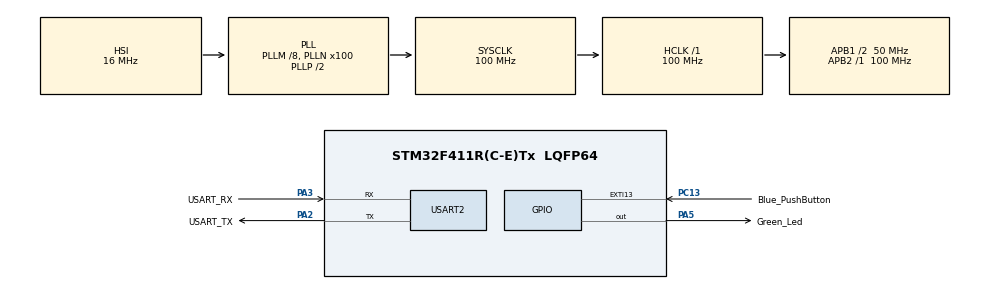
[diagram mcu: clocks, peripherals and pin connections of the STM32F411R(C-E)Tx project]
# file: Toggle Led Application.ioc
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Mcu.Family=STM32F4
Mcu.Name=STM32F411R(C-E)Tx
Mcu.Package=LQFP64
NVIC.EXTI15_10_IRQn=true\:0\:0\:false\:false\:true\:true\:true\:true
NVIC.PriorityGroup=NVIC_PRIORITYGROUP_0
NVIC.TIM1_UP_TIM10_IRQn=true\:0\:0\:false\:false\:true\:true\:true\:true
PA13.GPIO_Label=TMS
PA13.Mode=Serial_Wire
PA13.Signal=SYS_JTMS-SWDIO
PA14.GPIO_Label=TCK
PA14.Mode=Serial_Wire
PA14.Signal=SYS_JTCK-SWCLK
PA2.GPIO_Label=USART_TX
PA2.Mode=Asynchronous
PA2.Signal=USART2_TX
PA3.GPIO_Label=USART_RX
PA3.Mode=Asynchronous
PA3.Signal=USART2_RX
PA5.GPIO_Label=Green_Led
PA5.Signal=GPIO_Output
PB3.GPIO_Label=SWO
PB3.Signal=SYS_JTDO-SWO
PC13-ANTI_TAMP.GPIO_Label=Blue_PushButton
PC13-ANTI_TAMP.GPIO_ModeDefaultEXTI=GPIO_MODE_IT_FALLING
PC13-ANTI_TAMP.Signal=GPXTI13
ProjectManager.HeapSize=0x200
ProjectManager.StackSize=0x400
ProjectManager.TargetToolchain=MDK-ARM V5.32
RCC.48MHZClocksFreq_Value=50000000
RCC.AHBFreq_Value=100000000
RCC.APB1CLKDivider=RCC_HCLK_DIV2
RCC.APB1Freq_Value=50000000
RCC.APB1TimFreq_Value=100000000
RCC.APB2Freq_Value=100000000
RCC.APB2TimFreq_Value=100000000
RCC.CortexFreq_Value=100000000
RCC.FLatency-AdvancedSettings=FLASH_LATENCY_3
RCC.HCLKFreq_Value=100000000
RCC.HSE_VALUE=8000000
RCC.HSI_VALUE=16000000
RCC.LSE_VALUE=32768
RCC.PLLM=8
RCC.PLLN=100
RCC.SYSCLKFreq_VALUE=100000000
RCC.SYSCLKSource=RCC_SYSCLKSOURCE_PLLCLK
RCC.VCOOutputFreq_Value=200000000
TIM10.AutoReloadPreload=TIM_AUTORELOAD_PRELOAD_ENABLE
TIM10.Period=999
TIM10.Prescaler=99
USART2.VirtualMode=VM_ASYNC
VP_TIM10_VS_ClockSourceINT.Mode=Enable_Timer
board=NUCLEO-F411RE

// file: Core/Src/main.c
/* USER CODE BEGIN Header */
/**
  ******************************************************************************
  * @file           : main.c
  * @brief          : Main program body
  ******************************************************************************
  * @attention
  *
  * Copyright (c) 2026 STMicroelectronics.
  * All rights reserved.
  *
  * This software is licensed under terms that can be found in the LICENSE file
  * in the root directory of this software component.
  * If no LICENSE file comes with this software, it is provided AS-IS.
  *
  ******************************************************************************
  */
/* USER CODE END Header */
#include "main.h"
#include "tim.h"
#include "usart.h"
#include "gpio.h"

/* USER CODE BEGIN PV */

volatile uint16_t timer_counter = 0;
volatile uint16_t Led_Delay = 100;

/* USER CODE END PV */

void SystemClock_Config(void);

int main(void)
{

  /* MCU Configuration--------------------------------------------------------*/

  /* Reset of all peripherals, Initializes the Flash interface and the Systick. */
  HAL_Init();
  __enable_irq();

  /* Configure the system clock */
  SystemClock_Config();

  /* Initialize all configured peripherals */
  MX_GPIO_Init();
  MX_USART2_UART_Init();
  MX_TIM10_Init();
  /* USER CODE BEGIN 2 */

	HAL_TIM_Base_Start_IT(&htim10);

  /* USER CODE END 2 */

  /* Infinite loop */
  while (1)
  {
	if ( timer_counter >= Led_Delay){
		timer_counter = 0;
		HAL_GPIO_TogglePin(Green_Led_GPIO_Port , Green_Led_Pin);
	}
  }
}

void SystemClock_Config(void)
{
  RCC_OscInitTypeDef RCC_OscInitStruct = {0};
  RCC_ClkInitTypeDef RCC_ClkInitStruct = {0};

  /** Configure the main internal regulator output voltage
  */
  __HAL_RCC_PWR_CLK_ENABLE();
  __HAL_PWR_VOLTAGESCALING_CONFIG(PWR_REGULATOR_VOLTAGE_SCALE1);

  /** Initializes the RCC Oscillators according to the specified parameters
  * in the RCC_OscInitTypeDef structure.
  */
  RCC_OscInitStruct.OscillatorType = RCC_OSCILLATORTYPE_HSI;
  RCC_OscInitStruct.HSIState = RCC_HSI_ON;
  RCC_OscInitStruct.HSICalibrationValue = RCC_HSICALIBRATION_DEFAULT;
  RCC_OscInitStruct.PLL.PLLState = RCC_PLL_ON;
  RCC_OscInitStruct.PLL.PLLSource = RCC_PLLSOURCE_HSI;
  RCC_OscInitStruct.PLL.PLLM = 8;
  RCC_OscInitStruct.PLL.PLLN = 100;
  RCC_OscInitStruct.PLL.PLLP = RCC_PLLP_DIV2;
  RCC_OscInitStruct.PLL.PLLQ = 4;
  if (HAL_RCC_OscConfig(&RCC_OscInitStruct) != HAL_OK)
  {
    Error_Handler();
  }

  /** Initializes the CPU, AHB and APB buses clocks
  */
  RCC_ClkInitStruct.ClockType = RCC_CLOCKTYPE_HCLK|RCC_CLOCKTYPE_SYSCLK
                              |RCC_CLOCKTYPE_PCLK1|RCC_CLOCKTYPE_PCLK2;
  RCC_ClkInitStruct.SYSCLKSource = RCC_SYSCLKSOURCE_PLLCLK;
  RCC_ClkInitStruct.AHBCLKDivider = RCC_SYSCLK_DIV1;
  RCC_ClkInitStruct.APB1CLKDivider = RCC_HCLK_DIV2;
  RCC_ClkInitStruct.APB2CLKDivider = RCC_HCLK_DIV1;

  if (HAL_RCC_ClockConfig(&RCC_ClkInitStruct, FLASH_LATENCY_3) != HAL_OK)
  {
    Error_Handler();
  }
}

/* USER CODE BEGIN 4 */

void HAL_TIM_PeriodElapsedCallback(TIM_HandleTypeDef *htim){
	if(htim->Instance == TIM10){
		timer_counter++;
	}

}

/* USER CODE END 4 */

void Error_Handler(void)
{
  __disable_irq();
  while (1)
  {
  }
}
